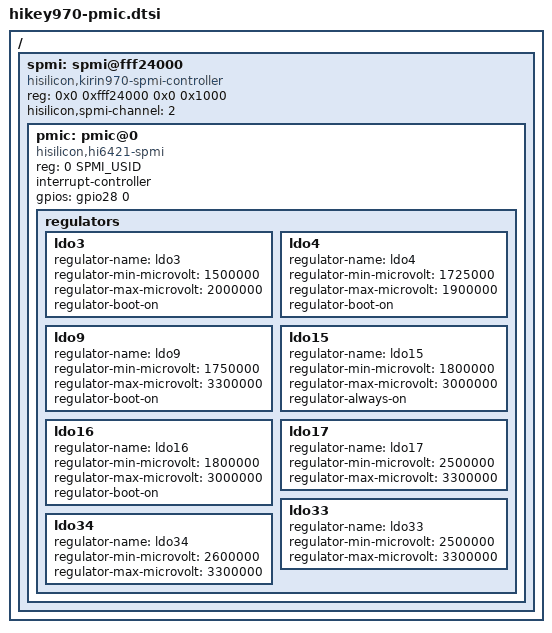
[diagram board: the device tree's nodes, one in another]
// SPDX-License-Identifier: GPL-2.0
/*
 * dts file for Hi6421v600 SPMI PMIC used at the HiKey970 Development Board
 *
 * Copyright (C) 2020, Huawei Tech. Co., Ltd.
 */

#include <dt-bindings/spmi/spmi.h>

/ {
	spmi: spmi@fff24000 {
		compatible = "hisilicon,kirin970-spmi-controller";
		reg = <0x0 0xfff24000 0x0 0x1000>;
		#address-cells = <2>;
		#size-cells = <0>;
		hisilicon,spmi-channel = <2>;

		pmic: pmic@0 {
			compatible = "hisilicon,hi6421-spmi";
			reg = <0 SPMI_USID>;

			#interrupt-cells = <2>;
			interrupt-controller;
			gpios = <&gpio28 0 0>;

			regulators {
				ldo3: ldo3 { /* HDMI */
					regulator-name = "ldo3";
					regulator-min-microvolt = <1500000>;
					regulator-max-microvolt = <2000000>;
					regulator-boot-on;
				};

				ldo4: ldo4 { /* 40 PIN */
					regulator-name = "ldo4";
					regulator-min-microvolt = <1725000>;
					regulator-max-microvolt = <1900000>;
					regulator-boot-on;
				};

				ldo9: ldo9 { /* SDCARD I/O */
					regulator-name = "ldo9";
					regulator-min-microvolt = <1750000>;
					regulator-max-microvolt = <3300000>;
					regulator-boot-on;
				};

				ldo15: ldo15 { /* UFS */
					regulator-name = "ldo15";
					regulator-min-microvolt = <1800000>;
					regulator-max-microvolt = <3000000>;
					regulator-always-on;
				};

				ldo16: ldo16 { /* SD */
					regulator-name = "ldo16";
					regulator-min-microvolt = <1800000>;
					regulator-max-microvolt = <3000000>;
					regulator-boot-on;
				};

				ldo17: ldo17 { /* USB HUB */
					regulator-name = "ldo17";
					regulator-min-microvolt = <2500000>;
					regulator-max-microvolt = <3300000>;
				};

				ldo33: ldo33 { /* PEX8606 */
					regulator-name = "ldo33";
					regulator-min-microvolt = <2500000>;
					regulator-max-microvolt = <3300000>;
				};

				ldo34: ldo34 { /* GPS AUX IN VDD */
					regulator-name = "ldo34";
					regulator-min-microvolt = <2600000>;
					regulator-max-microvolt = <3300000>;
				};
			};
		};
	};
};
